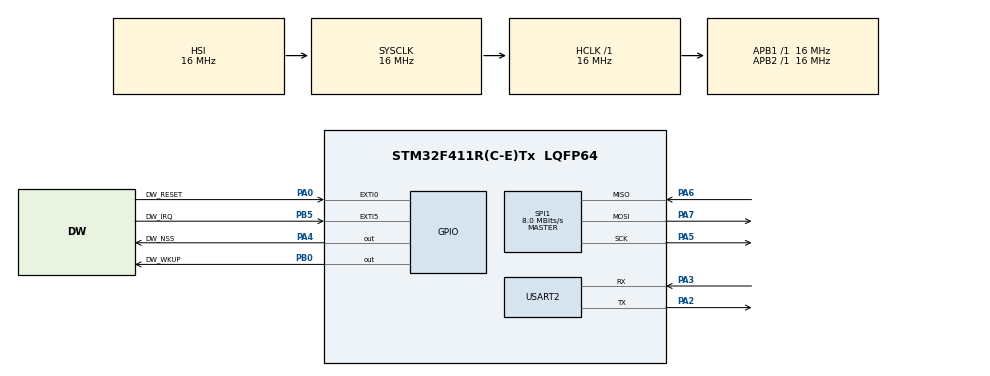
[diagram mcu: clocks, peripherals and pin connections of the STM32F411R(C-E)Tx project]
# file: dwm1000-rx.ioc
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Mcu.Family=STM32F4
Mcu.Name=STM32F411R(C-E)Tx
Mcu.Package=LQFP64
NVIC.EXTI0_IRQn=true\:3\:0\:true\:false\:true\:true\:true\:true
NVIC.EXTI9_5_IRQn=true\:4\:0\:true\:false\:true\:true\:true\:true
NVIC.PriorityGroup=NVIC_PRIORITYGROUP_4
PA0-WKUP.GPIO_Label=DW_RESET
PA0-WKUP.Signal=GPXTI0
PA2.Mode=Asynchronous
PA2.Signal=USART2_TX
PA3.Mode=Asynchronous
PA3.Signal=USART2_RX
PA4.GPIO_Label=DW_NSS
PA4.PinState=GPIO_PIN_SET
PA4.Signal=GPIO_Output
PA5.Mode=Full_Duplex_Master
PA5.Signal=SPI1_SCK
PA6.Mode=Full_Duplex_Master
PA6.Signal=SPI1_MISO
PA7.Mode=Full_Duplex_Master
PA7.Signal=SPI1_MOSI
PB0.GPIO_Label=DW_WKUP
PB0.GPIO_ModeDefaultOutputPP=GPIO_MODE_OUTPUT_OD
PB0.GPIO_PuPd=GPIO_NOPULL
PB0.PinState=GPIO_PIN_SET
PB0.Signal=GPIO_Output
PB5.GPIO_Label=DW_IRQ
PB5.Signal=GPXTI5
PC14-OSC32_IN.Mode=LSE-External-Oscillator
PC14-OSC32_IN.Signal=RCC_OSC32_IN
PC15-OSC32_OUT.Mode=LSE-External-Oscillator
PC15-OSC32_OUT.Signal=RCC_OSC32_OUT
PH0\ -\ OSC_IN.Mode=HSE-External-Oscillator
PH0\ -\ OSC_IN.Signal=RCC_OSC_IN
PH1\ -\ OSC_OUT.Mode=HSE-External-Oscillator
PH1\ -\ OSC_OUT.Signal=RCC_OSC_OUT
ProjectManager.HeapSize=0x200
ProjectManager.StackSize=0x400
ProjectManager.TargetToolchain=STM32CubeIDE
RCC.AHBFreq_Value=16000000
RCC.APB1Freq_Value=16000000
RCC.APB2Freq_Value=16000000
RCC.CortexFreq_Value=16000000
RCC.HSE_VALUE=25000000
RCC.HSI_VALUE=16000000
RCC.SYSCLKFreq_VALUE=16000000
RCC.VCOOutputFreq_Value=192000000
SPI1.CalculateBaudRate=8.0 MBits/s
SPI1.Direction=SPI_DIRECTION_2LINES
SPI1.Mode=SPI_MODE_MASTER
SPI1.VirtualType=VM_MASTER
USART2.VirtualMode=VM_ASYNC
board=custom

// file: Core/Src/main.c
/* USER CODE BEGIN Header */
/**
  ******************************************************************************
  * @file           : main.c
  * @brief          : Main program body
  ******************************************************************************
  * @attention
  *
  * Copyright (c) 2023 STMicroelectronics.
  * All rights reserved.
  *
  * This software is licensed under terms that can be found in the LICENSE file
  * in the root directory of this software component.
  * If no LICENSE file comes with this software, it is provided AS-IS.
  *
  ******************************************************************************
  */
/* USER CODE END Header */
#include "main.h"
#include "spi.h"
#include "usart.h"
#include "gpio.h"

void SystemClock_Config(void);
static void MX_NVIC_Init(void);

/* USER CODE BEGIN 0 */
extern int dw_main(void);
/* USER CODE END 0 */

int main(void)
{

  /* MCU Configuration--------------------------------------------------------*/

  /* Reset of all peripherals, Initializes the Flash interface and the Systick. */
  HAL_Init();

  /* Configure the system clock */
  SystemClock_Config();

  /* Initialize all configured peripherals */
  MX_GPIO_Init();
  MX_SPI1_Init();
  MX_USART2_UART_Init();
  /* USER CODE BEGIN 2 */
  MX_NVIC_Init();
  setup_DW1000RSTnIRQ(0);
  dw_main();
  /* USER CODE END 2 */

  /* Infinite loop */
  while (1)
  {

  }
}

void SystemClock_Config(void)
{
  RCC_OscInitTypeDef RCC_OscInitStruct = {0};
  RCC_ClkInitTypeDef RCC_ClkInitStruct = {0};

  /** Configure the main internal regulator output voltage
  */
  __HAL_RCC_PWR_CLK_ENABLE();
  __HAL_PWR_VOLTAGESCALING_CONFIG(PWR_REGULATOR_VOLTAGE_SCALE1);

  /** Initializes the RCC Oscillators according to the specified parameters
  * in the RCC_OscInitTypeDef structure.
  */
  RCC_OscInitStruct.OscillatorType = RCC_OSCILLATORTYPE_HSI;
  RCC_OscInitStruct.HSIState = RCC_HSI_ON;
  RCC_OscInitStruct.HSICalibrationValue = RCC_HSICALIBRATION_DEFAULT;
  RCC_OscInitStruct.PLL.PLLState = RCC_PLL_NONE;
  if (HAL_RCC_OscConfig(&RCC_OscInitStruct) != HAL_OK)
  {
    Error_Handler();
  }

  /** Initializes the CPU, AHB and APB buses clocks
  */
  RCC_ClkInitStruct.ClockType = RCC_CLOCKTYPE_HCLK|RCC_CLOCKTYPE_SYSCLK
                              |RCC_CLOCKTYPE_PCLK1|RCC_CLOCKTYPE_PCLK2;
  RCC_ClkInitStruct.SYSCLKSource = RCC_SYSCLKSOURCE_HSI;
  RCC_ClkInitStruct.AHBCLKDivider = RCC_SYSCLK_DIV1;
  RCC_ClkInitStruct.APB1CLKDivider = RCC_HCLK_DIV1;
  RCC_ClkInitStruct.APB2CLKDivider = RCC_HCLK_DIV1;

  if (HAL_RCC_ClockConfig(&RCC_ClkInitStruct, FLASH_LATENCY_0) != HAL_OK)
  {
    Error_Handler();
  }
}

/* USER CODE BEGIN 4 */
/** NVIC Configuration
*/
static void MX_NVIC_Init(void)
{
  /* EXTI0_IRQn interrupt configuration */
  HAL_NVIC_SetPriority(EXTI0_IRQn, 3, 0);
  HAL_NVIC_EnableIRQ(EXTI0_IRQn);
  /* EXTI9_5_IRQn interrupt configuration */
  HAL_NVIC_SetPriority(EXTI9_5_IRQn, 4, 0);
  HAL_NVIC_EnableIRQ(EXTI9_5_IRQn);
  /* OTG_FS_IRQn interrupt configuration */
//  HAL_NVIC_SetPriority(OTG_FS_IRQn, 7, 0);
//  HAL_NVIC_EnableIRQ(OTG_FS_IRQn);
}
/* USER CODE END 4 */

void Error_Handler(void)
{
  __disable_irq();
  while (1)
  {
  }
}
